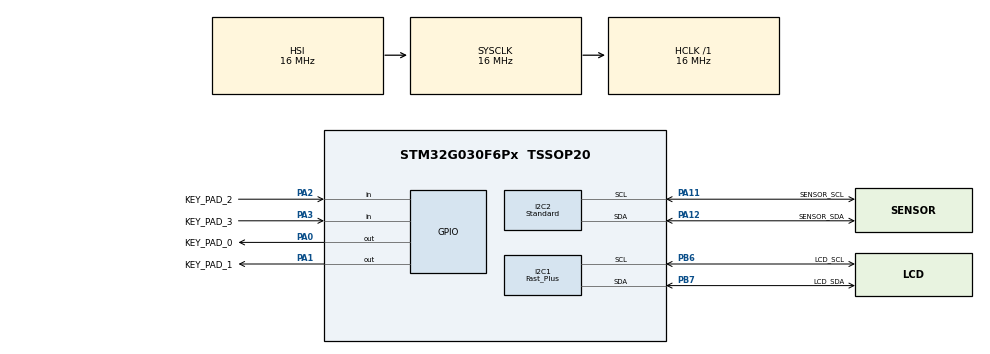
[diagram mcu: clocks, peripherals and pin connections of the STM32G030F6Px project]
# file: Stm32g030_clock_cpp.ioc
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I2C1.I2C_Speed_Mode=I2C_Fast_Plus
I2C1.Timing=0x00200105
I2C2.I2C_Speed_Mode=I2C_Standard
I2C2.Timing=0x00503D58
Mcu.Family=STM32G0
Mcu.Name=STM32G030F6Px
Mcu.Package=TSSOP20
NVIC.RCC_IRQn=true\:0\:0\:false\:false\:true\:true\:false\:true
PA0.GPIO_Label=KEY_PAD_0
PA0.GPIO_Speed=GPIO_SPEED_FREQ_VERY_HIGH
PA0.Signal=GPIO_Output
PA1.GPIO_Label=KEY_PAD_1
PA1.GPIO_Speed=GPIO_SPEED_FREQ_VERY_HIGH
PA1.Signal=GPIO_Output
PA11\ [PA9].GPIO_Label=SENSOR_SCL
PA11\ [PA9].GPIO_Pu=GPIO_PULLUP
PA11\ [PA9].GPIO_Speed=GPIO_SPEED_FREQ_VERY_HIGH
PA11\ [PA9].Mode=I2C
PA11\ [PA9].Signal=I2C2_SCL
PA12\ [PA10].GPIO_Label=SENSOR_SDA
PA12\ [PA10].GPIO_Pu=GPIO_PULLUP
PA12\ [PA10].GPIO_Speed=GPIO_SPEED_FREQ_VERY_HIGH
PA12\ [PA10].Mode=I2C
PA12\ [PA10].Signal=I2C2_SDA
PA13.Mode=Serial_Wire
PA13.Signal=SYS_SWDIO
PA14-BOOT0.Mode=Serial_Wire
PA14-BOOT0.Signal=SYS_SWCLK
PA14-BOOT0__PA15.StandardMode=true
PA2.GPIO_Label=KEY_PAD_2
PA2.GPIO_PuPd=GPIO_PULLUP
PA2.Signal=GPIO_Input
PA3.GPIO_Label=KEY_PAD_3
PA3.GPIO_PuPd=GPIO_PULLUP
PA3.Signal=GPIO_Input
PB0__PB1__PB2__PA8.StandardMode=true
PB3__PB4__PB5__PB6.StandardMode=true
PB6.GPIO_FM6=SYSCFG_FASTMODEPLUS_PB6
PB6.GPIO_Label=LCD_SCL
PB6.GPIO_Pu=GPIO_PULLUP
PB6.GPIO_Speed=GPIO_SPEED_FREQ_VERY_HIGH
PB6.Mode=I2C
PB6.Signal=I2C1_SCL
PB7.GPIO_FM7=SYSCFG_FASTMODEPLUS_PB7
PB7.GPIO_Label=LCD_SDA
PB7.GPIO_Pu=GPIO_PULLUP
PB7.GPIO_Speed=GPIO_SPEED_FREQ_VERY_HIGH
PB7.Mode=I2C
PB7.Signal=I2C1_SDA
PB7__PB8.StandardMode=true
PC14-OSC32_IN\ (PC14).Mode=LSE-External-Oscillator
PC14-OSC32_IN\ (PC14).Signal=RCC_OSC32_IN
PC14-OSC32_IN\ (PC14)__PB9.StandardMode=true
PC15-OSC32_OUT\ (PC15).Mode=LSE-External-Oscillator
PC15-OSC32_OUT\ (PC15).Signal=RCC_OSC32_OUT
ProjectManager.HeapSize=0x200
ProjectManager.StackSize=0x400
ProjectManager.TargetToolchain=STM32CubeIDE
RCC.ADCFreq_Value=16000000
RCC.AHBFreq_Value=16000000
RCC.CortexFreq_Value=16000000
RCC.EXTERNAL_CLOCK_VALUE=12288000
RCC.HCLKFreq_Value=16000000
RCC.HSE_VALUE=8000000
RCC.HSI_VALUE=16000000
RCC.RTCClockSelection=RCC_RTCCLKSOURCE_LSE
RCC.SYSCLKFreq_VALUE=16000000
RCC.VCOOutputFreq_Value=128000000
RTC.Date=25
RTC.Format=RTC_FORMAT_BIN
RTC.Month=RTC_MONTH_AUGUST
RTC.WeekDay=RTC_WEEKDAY_FRIDAY
VP_RTC_VS_RTC_Activate.Mode=RTC_Enabled
VP_RTC_VS_RTC_Calendar.Mode=RTC_Calendar
board=custom

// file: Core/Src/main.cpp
/* USER CODE BEGIN Header */
/**
  ******************************************************************************
  * @file           : main.c
  * @brief          : Main program body
  ******************************************************************************
  * @attention
  *
  * Copyright (c) 2024 STMicroelectronics.
  * All rights reserved.
  *
  * This software is licensed under terms that can be found in the LICENSE file
  * in the root directory of this software component.
  * If no LICENSE file comes with this software, it is provided AS-IS.
  *
  ******************************************************************************
  */
/* USER CODE END Header */
#include "main.h"

/* USER CODE BEGIN Includes */
#include <string>

#include "key.h"

#include "app.h"
/* USER CODE END Includes */

I2C_HandleTypeDef hi2c1;
I2C_HandleTypeDef hi2c2;

RTC_HandleTypeDef hrtc;

void SystemClock_Config(void);
static void MX_GPIO_Init(void);
static void MX_I2C1_Init(void);
static void MX_RTC_Init(void);
static void MX_I2C2_Init(void);

int main(void)
{

  /* MCU Configuration--------------------------------------------------------*/

  /* Reset of all peripherals, Initializes the Flash interface and the Systick. */
  HAL_Init();

  /* Configure the system clock */
  SystemClock_Config();

  /* Initialize all configured peripherals */
  MX_GPIO_Init();
  MX_I2C1_Init();
  MX_RTC_Init();
  MX_I2C2_Init();
  /* USER CODE BEGIN 2 */
  app main_app;
  main_app.main();
  /* USER CODE END 2 */

  /* Infinite loop */
  /* USER CODE BEGIN WHILE */
  while (1)
  {
	  //We should never reach here

    /* USER CODE END WHILE */

  }
}

void SystemClock_Config(void)
{
  RCC_OscInitTypeDef RCC_OscInitStruct = {0};
  RCC_ClkInitTypeDef RCC_ClkInitStruct = {0};

  /** Configure the main internal regulator output voltage
  */
  HAL_PWREx_ControlVoltageScaling(PWR_REGULATOR_VOLTAGE_SCALE1);

  /** Configure LSE Drive Capability
  */
  HAL_PWR_EnableBkUpAccess();
  __HAL_RCC_LSEDRIVE_CONFIG(RCC_LSEDRIVE_LOW);

  /** Initializes the RCC Oscillators according to the specified parameters
  * in the RCC_OscInitTypeDef structure.
  */
  RCC_OscInitStruct.OscillatorType = RCC_OSCILLATORTYPE_HSI|RCC_OSCILLATORTYPE_LSE;
  RCC_OscInitStruct.LSEState = RCC_LSE_ON;
  RCC_OscInitStruct.HSIState = RCC_HSI_ON;
  RCC_OscInitStruct.HSIDiv = RCC_HSI_DIV1;
  RCC_OscInitStruct.HSICalibrationValue = RCC_HSICALIBRATION_DEFAULT;
  RCC_OscInitStruct.PLL.PLLState = RCC_PLL_NONE;
  if (HAL_RCC_OscConfig(&RCC_OscInitStruct) != HAL_OK)
  {
    Error_Handler();
  }

  /** Initializes the CPU, AHB and APB buses clocks
  */
  RCC_ClkInitStruct.ClockType = RCC_CLOCKTYPE_HCLK|RCC_CLOCKTYPE_SYSCLK
                              |RCC_CLOCKTYPE_PCLK1;
  RCC_ClkInitStruct.SYSCLKSource = RCC_SYSCLKSOURCE_HSI;
  RCC_ClkInitStruct.AHBCLKDivider = RCC_SYSCLK_DIV1;
  RCC_ClkInitStruct.APB1CLKDivider = RCC_HCLK_DIV1;

  if (HAL_RCC_ClockConfig(&RCC_ClkInitStruct, FLASH_LATENCY_0) != HAL_OK)
  {
    Error_Handler();
  }
}

static void MX_I2C1_Init(void)
{

  hi2c1.Instance = I2C1;
  hi2c1.Init.Timing = 0x00200105;
  hi2c1.Init.OwnAddress1 = 0;
  hi2c1.Init.AddressingMode = I2C_ADDRESSINGMODE_7BIT;
  hi2c1.Init.DualAddressMode = I2C_DUALADDRESS_DISABLE;
  hi2c1.Init.OwnAddress2 = 0;
  hi2c1.Init.OwnAddress2Masks = I2C_OA2_NOMASK;
  hi2c1.Init.GeneralCallMode = I2C_GENERALCALL_DISABLE;
  hi2c1.Init.NoStretchMode = I2C_NOSTRETCH_DISABLE;
  if (HAL_I2C_Init(&hi2c1) != HAL_OK)
  {
    Error_Handler();
  }

  /** Configure Analogue filter
  */
  if (HAL_I2CEx_ConfigAnalogFilter(&hi2c1, I2C_ANALOGFILTER_ENABLE) != HAL_OK)
  {
    Error_Handler();
  }

  /** Configure Digital filter
  */
  if (HAL_I2CEx_ConfigDigitalFilter(&hi2c1, 0) != HAL_OK)
  {
    Error_Handler();
  }

  /** I2C Fast mode Plus enable
  */
  HAL_I2CEx_EnableFastModePlus(I2C_FASTMODEPLUS_I2C1);

}

static void MX_I2C2_Init(void)
{

  hi2c2.Instance = I2C2;
  hi2c2.Init.Timing = 0x00503D58;
  hi2c2.Init.OwnAddress1 = 0;
  hi2c2.Init.AddressingMode = I2C_ADDRESSINGMODE_7BIT;
  hi2c2.Init.DualAddressMode = I2C_DUALADDRESS_DISABLE;
  hi2c2.Init.OwnAddress2 = 0;
  hi2c2.Init.OwnAddress2Masks = I2C_OA2_NOMASK;
  hi2c2.Init.GeneralCallMode = I2C_GENERALCALL_DISABLE;
  hi2c2.Init.NoStretchMode = I2C_NOSTRETCH_DISABLE;
  if (HAL_I2C_Init(&hi2c2) != HAL_OK)
  {
    Error_Handler();
  }

  /** Configure Analogue filter
  */
  if (HAL_I2CEx_ConfigAnalogFilter(&hi2c2, I2C_ANALOGFILTER_ENABLE) != HAL_OK)
  {
    Error_Handler();
  }

  /** Configure Digital filter
  */
  if (HAL_I2CEx_ConfigDigitalFilter(&hi2c2, 0) != HAL_OK)
  {
    Error_Handler();
  }

}

static void MX_RTC_Init(void)
{

  RTC_TimeTypeDef sTime = {0};
  RTC_DateTypeDef sDate = {0};

  /** Initialize RTC Only
  */
  hrtc.Instance = RTC;
  hrtc.Init.HourFormat = RTC_HOURFORMAT_24;
  hrtc.Init.AsynchPrediv = 127;
  hrtc.Init.SynchPrediv = 255;
  hrtc.Init.OutPut = RTC_OUTPUT_DISABLE;
  hrtc.Init.OutPutRemap = RTC_OUTPUT_REMAP_NONE;
  hrtc.Init.OutPutPolarity = RTC_OUTPUT_POLARITY_HIGH;
  hrtc.Init.OutPutType = RTC_OUTPUT_TYPE_OPENDRAIN;
  hrtc.Init.OutPutPullUp = RTC_OUTPUT_PULLUP_NONE;
  if (HAL_RTC_Init(&hrtc) != HAL_OK)
  {
    Error_Handler();
  }

  /** Initialize RTC and set the Time and Date
  */
  sTime.Hours = 0;
  sTime.Minutes = 0;
  sTime.Seconds = 0;
  sTime.SubSeconds = 0;
  sTime.DayLightSaving = RTC_DAYLIGHTSAVING_NONE;
  sTime.StoreOperation = RTC_STOREOPERATION_RESET;
  if (HAL_RTC_SetTime(&hrtc, &sTime, RTC_FORMAT_BIN) != HAL_OK)
  {
    Error_Handler();
  }
  sDate.WeekDay = RTC_WEEKDAY_FRIDAY;
  sDate.Month = RTC_MONTH_AUGUST;
  sDate.Date = 25;
  sDate.Year = 0;

  if (HAL_RTC_SetDate(&hrtc, &sDate, RTC_FORMAT_BIN) != HAL_OK)
  {
    Error_Handler();
  }

}

static void MX_GPIO_Init(void)
{
  GPIO_InitTypeDef GPIO_InitStruct = {0};

  /* GPIO Ports Clock Enable */
  __HAL_RCC_GPIOB_CLK_ENABLE();
  __HAL_RCC_GPIOC_CLK_ENABLE();
  __HAL_RCC_GPIOA_CLK_ENABLE();

  /*Configure GPIO pin Output Level */
  HAL_GPIO_WritePin(GPIOA, KEY_PAD_0_Pin|KEY_PAD_1_Pin, GPIO_PIN_RESET);

  /*Configure GPIO pins : KEY_PAD_0_Pin KEY_PAD_1_Pin */
  GPIO_InitStruct.Pin = KEY_PAD_0_Pin|KEY_PAD_1_Pin;
  GPIO_InitStruct.Mode = GPIO_MODE_OUTPUT_PP;
  GPIO_InitStruct.Pull = GPIO_NOPULL;
  GPIO_InitStruct.Speed = GPIO_SPEED_FREQ_VERY_HIGH;
  HAL_GPIO_Init(GPIOA, &GPIO_InitStruct);

  /*Configure GPIO pins : KEY_PAD_2_Pin KEY_PAD_3_Pin */
  GPIO_InitStruct.Pin = KEY_PAD_2_Pin|KEY_PAD_3_Pin;
  GPIO_InitStruct.Mode = GPIO_MODE_INPUT;
  GPIO_InitStruct.Pull = GPIO_PULLUP;
  HAL_GPIO_Init(GPIOA, &GPIO_InitStruct);

}

void Error_Handler(void)
{
  __disable_irq();
  while (1)
  {
  }
}
